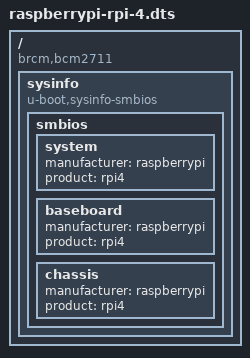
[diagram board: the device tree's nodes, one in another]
// SMBIOS tables support for default Raspberry Pi 4
/dts-v1/;
/plugin/;

/ {
	compatible = "brcm,bcm2711";
	fragment@0 {
		target-path = "/";
		__overlay__ {
			sysinfo {
				compatible = "u-boot,sysinfo-smbios";
				smbios {
					system {
						manufacturer = "raspberrypi";
						product = "rpi4";
					};
					baseboard {
						manufacturer = "raspberrypi";
						product = "rpi4";
					};
					chassis {
						manufacturer = "raspberrypi";
						product = "rpi4";
					};
				};
			};
		};
	};
};
